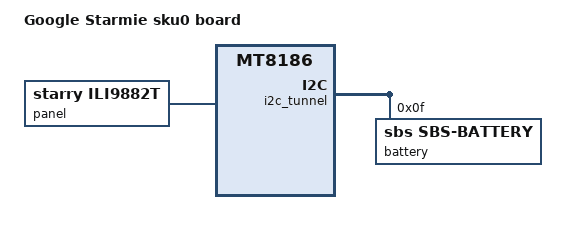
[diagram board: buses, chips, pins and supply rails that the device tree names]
// SPDX-License-Identifier: (GPL-2.0 OR MIT)
/*
 * Copyright 2023 Google LLC
 */

/dts-v1/;
#include "mt8186-corsola-starmie.dtsi"

/ {
	model = "Google Starmie sku0 board";
	compatible = "google,starmie-sku0", "google,starmie-sku2",
		     "google,starmie-sku3", "google,starmie",
		     "mediatek,mt8186";
};

&panel {
	compatible = "starry,ili9882t";
};

&i2c_tunnel {
	/delete-node/ sbs-battery@b;

	battery: sbs-battery@f {
		compatible = "sbs,sbs-battery";
		reg = <0xf>;
		sbs,i2c-retry-count = <2>;
		sbs,poll-retry-count = <1>;
	};
};
